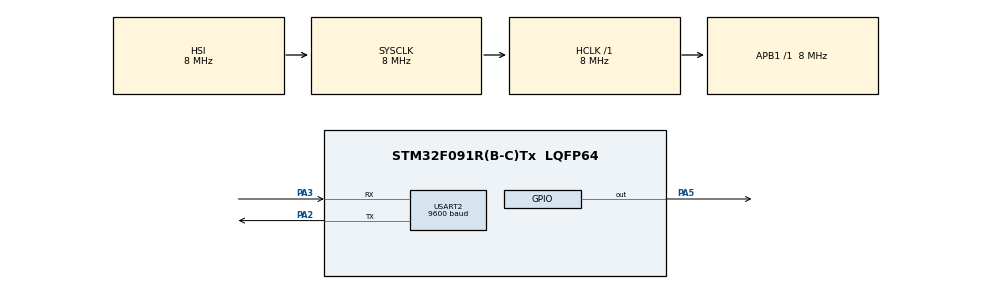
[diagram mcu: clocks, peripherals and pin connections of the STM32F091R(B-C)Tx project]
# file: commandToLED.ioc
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Mcu.Family=STM32F0
Mcu.Name=STM32F091R(B-C)Tx
Mcu.Package=LQFP64
NVIC.USART2_IRQn=true\:0\:0\:false\:false\:true\:true\:true
PA2.Mode=Asynchronous
PA2.Signal=USART2_TX
PA3.Mode=Asynchronous
PA3.Signal=USART2_RX
PA5.Signal=GPIO_Output
ProjectManager.HeapSize=0x200
ProjectManager.StackSize=0x400
ProjectManager.TargetToolchain=SW4STM32
RCC.AHBFreq_Value=8000000
RCC.APB1Freq_Value=8000000
RCC.APB1TimFreq_Value=8000000
RCC.FLatency-AdvancedSettings=FLASH_LATENCY_0
RCC.HCLKFreq_Value=8000000
RCC.PLLDivider=RCC_PREDIV_DIV2
RCC.PLLMUL=RCC_PLL_MUL12
RCC.PREFETCH_ENABLE-AdvancedSettings=1
RCC.SYSCLKFreq_VALUE=8000000
USART2.BaudRate=9600
USART2.VirtualMode-Asynchronous=VM_ASYNC
board=NUCLEO-F091RC

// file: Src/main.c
/* USER CODE BEGIN Header */
/**
  ******************************************************************************
  * @file           : main.c
  * @brief          : Main program body
  ******************************************************************************
  * @attention
  *
  * <h2><center>&copy; Copyright (c) 2020 STMicroelectronics.
  * All rights reserved.</center></h2>
  *
  * This software component is licensed by ST under BSD 3-Clause license,
  * the "License"; You may not use this file except in compliance with the
  * License. You may obtain a copy of the License at:
  *                        opensource.org/licenses/BSD-3-Clause
  *
  ******************************************************************************
  */
/* USER CODE END Header */

#include "main.h"

/* USER CODE BEGIN Includes */
#include "string.h"
/* USER CODE END Includes */

UART_HandleTypeDef huart2;

/* USER CODE BEGIN PV */
uint8_t i, fl, data[1], buff[100];
char LEDon[2] = "on", LEDoff[3] = "off"; //strings com os comandos

/* USER CODE END PV */

void SystemClock_Config(void);
static void MX_GPIO_Init(void);
static void MX_USART2_UART_Init(void);

int main(void)
{

  /* MCU Configuration--------------------------------------------------------*/

  /* Reset of all peripherals, Initializes the Flash interface and the Systick. */
  HAL_Init();

  /* Configure the system clock */
  SystemClock_Config();

  /* Initialize all configured peripherals */
  MX_GPIO_Init();
  MX_USART2_UART_Init();
  /* USER CODE BEGIN 2 */
HAL_UART_Receive_IT(&huart2,&data,1); //iniciar interrupçao

i = 0;
fl = 0;
  /* USER CODE END 2 */

  /* Infinite loop */
  while (1)
  {

    /* USER CODE BEGIN 3 */
	  if (fl==1) //recebeu um enter, fl passou a 1
	  {
		  if(strncmp(&buff,&LEDon,2) == 0) //se o comando for "on"
		  {
			  HAL_GPIO_WritePin(GPIOA,GPIO_PIN_5,1); //ligar LED
		  }
		  else if(strncmp(&buff,&LEDoff,3) == 0) //se o comando for "off"
		  {
			  HAL_GPIO_WritePin(GPIOA,GPIO_PIN_5,0); //desligar LED
		  }
		  else
		  {
			  __NOP(); //fazer nada
		  }

		  fl = 0;
		  i = 0;
	  }
	  //HAL_UART_Receive_IT(&huart2,&data,1);
  }
  /* USER CODE END 3 */
}

void SystemClock_Config(void)
{
  RCC_OscInitTypeDef RCC_OscInitStruct = {0};
  RCC_ClkInitTypeDef RCC_ClkInitStruct = {0};
  RCC_PeriphCLKInitTypeDef PeriphClkInit = {0};

  /** Initializes the CPU, AHB and APB busses clocks
  */
  RCC_OscInitStruct.OscillatorType = RCC_OSCILLATORTYPE_HSI;
  RCC_OscInitStruct.HSIState = RCC_HSI_ON;
  RCC_OscInitStruct.HSICalibrationValue = RCC_HSICALIBRATION_DEFAULT;
  RCC_OscInitStruct.PLL.PLLState = RCC_PLL_NONE;
  if (HAL_RCC_OscConfig(&RCC_OscInitStruct) != HAL_OK)
  {
    Error_Handler();
  }
  /** Initializes the CPU, AHB and APB busses clocks
  */
  RCC_ClkInitStruct.ClockType = RCC_CLOCKTYPE_HCLK|RCC_CLOCKTYPE_SYSCLK
                              |RCC_CLOCKTYPE_PCLK1;
  RCC_ClkInitStruct.SYSCLKSource = RCC_SYSCLKSOURCE_HSI;
  RCC_ClkInitStruct.AHBCLKDivider = RCC_SYSCLK_DIV1;
  RCC_ClkInitStruct.APB1CLKDivider = RCC_HCLK_DIV1;

  if (HAL_RCC_ClockConfig(&RCC_ClkInitStruct, FLASH_LATENCY_0) != HAL_OK)
  {
    Error_Handler();
  }
  PeriphClkInit.PeriphClockSelection = RCC_PERIPHCLK_USART2;
  PeriphClkInit.Usart2ClockSelection = RCC_USART2CLKSOURCE_PCLK1;
  if (HAL_RCCEx_PeriphCLKConfig(&PeriphClkInit) != HAL_OK)
  {
    Error_Handler();
  }
}

static void MX_USART2_UART_Init(void)
{

  huart2.Instance = USART2;
  huart2.Init.BaudRate = 9600;
  huart2.Init.WordLength = UART_WORDLENGTH_8B;
  huart2.Init.StopBits = UART_STOPBITS_1;
  huart2.Init.Parity = UART_PARITY_NONE;
  huart2.Init.Mode = UART_MODE_TX_RX;
  huart2.Init.HwFlowCtl = UART_HWCONTROL_NONE;
  huart2.Init.OverSampling = UART_OVERSAMPLING_16;
  huart2.Init.OneBitSampling = UART_ONE_BIT_SAMPLE_DISABLE;
  huart2.AdvancedInit.AdvFeatureInit = UART_ADVFEATURE_NO_INIT;
  if (HAL_UART_Init(&huart2) != HAL_OK)
  {
    Error_Handler();
  }

}

static void MX_GPIO_Init(void)
{
  GPIO_InitTypeDef GPIO_InitStruct = {0};

  /* GPIO Ports Clock Enable */
  __HAL_RCC_GPIOA_CLK_ENABLE();

  /*Configure GPIO pin Output Level */
  HAL_GPIO_WritePin(GPIOA, GPIO_PIN_5, GPIO_PIN_RESET);

  /*Configure GPIO pin : PA5 */
  GPIO_InitStruct.Pin = GPIO_PIN_5;
  GPIO_InitStruct.Mode = GPIO_MODE_OUTPUT_PP;
  GPIO_InitStruct.Pull = GPIO_NOPULL;
  GPIO_InitStruct.Speed = GPIO_SPEED_FREQ_LOW;
  HAL_GPIO_Init(GPIOA, &GPIO_InitStruct);

}

/* USER CODE BEGIN 4 */
void HAL_UART_RxCpltCallback(UART_HandleTypeDef *huart)
{

	if(i == 0) //limpar o buffer
	{
		memset(&buff,0,sizeof buff); //preencher buffer com zeros
	}

	if(data[0] != 13) //o caracter não é "enter" (13 em ASCII)
	{
		buff[i] = data[0];
		i++;
	}

	else //data = 13
	{
		fl=1;
	}

	HAL_UART_Receive_IT(&huart2,&data,1); //iniciar interrupçao novamente

}

/* USER CODE END 4 */

void Error_Handler(void)
{
}

/************************ (C) COPYRIGHT STMicroelectronics *****END OF FILE****/
